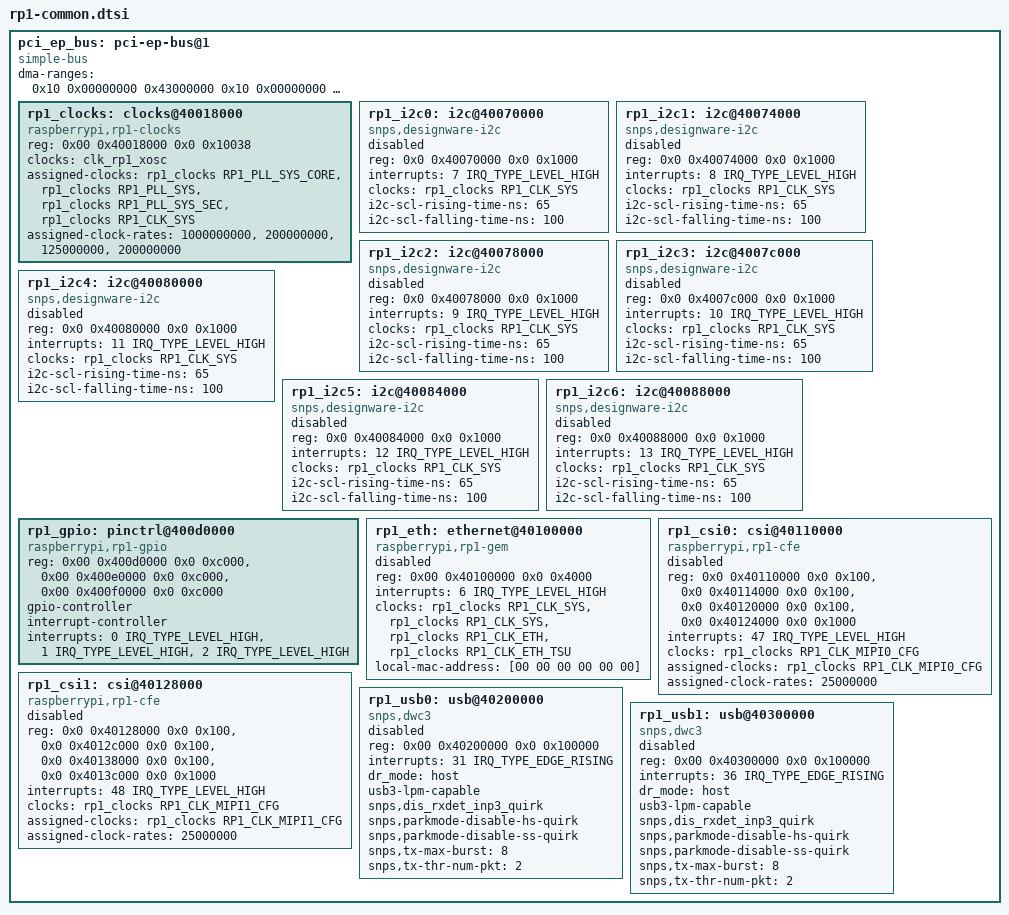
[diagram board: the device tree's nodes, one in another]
// SPDX-License-Identifier: (GPL-2.0 OR MIT)

#include <dt-bindings/gpio/gpio.h>
#include <dt-bindings/interrupt-controller/irq.h>
#include <dt-bindings/clock/raspberrypi,rp1-clocks.h>

pci_ep_bus: pci-ep-bus@1 {
	compatible = "simple-bus";
	ranges = <0x00 0x40000000  0x01 0x00 0x00000000  0x00 0x00400000>;
	dma-ranges = <0x10 0x00000000  0x43000000 0x10 0x00000000  0x10 0x00000000>;
	#address-cells = <2>;
	#size-cells = <2>;

	rp1_clocks: clocks@40018000 {
		compatible = "raspberrypi,rp1-clocks";
		reg = <0x00 0x40018000 0x0 0x10038>;
		#clock-cells = <1>;
		clocks = <&clk_rp1_xosc>;
		assigned-clocks = <&rp1_clocks RP1_PLL_SYS_CORE>,
				  <&rp1_clocks RP1_PLL_SYS>,
				  <&rp1_clocks RP1_PLL_SYS_SEC>,
				  <&rp1_clocks RP1_CLK_SYS>;
		assigned-clock-rates = <1000000000>, // RP1_PLL_SYS_CORE
				       <200000000>,  // RP1_PLL_SYS
				       <125000000>,  // RP1_PLL_SYS_SEC
				       <200000000>;  // RP1_CLK_SYS
	};

	rp1_i2c0: i2c@40070000 {
		compatible = "snps,designware-i2c";
		reg = <0x0 0x40070000  0x0 0x1000>;
		interrupts = <7 IRQ_TYPE_LEVEL_HIGH>;
		clocks = <&rp1_clocks RP1_CLK_SYS>;
		i2c-scl-rising-time-ns = <65>;
		i2c-scl-falling-time-ns = <100>;

		status = "disabled";
	};

	rp1_i2c1: i2c@40074000 {
		compatible = "snps,designware-i2c";
		reg = <0x0 0x40074000  0x0 0x1000>;
		interrupts = <8 IRQ_TYPE_LEVEL_HIGH>;
		clocks = <&rp1_clocks RP1_CLK_SYS>;
		i2c-scl-rising-time-ns = <65>;
		i2c-scl-falling-time-ns = <100>;

		status = "disabled";
	};

	rp1_i2c2: i2c@40078000 {
		compatible = "snps,designware-i2c";
		reg = <0x0 0x40078000  0x0 0x1000>;
		interrupts = <9 IRQ_TYPE_LEVEL_HIGH>;
		clocks = <&rp1_clocks RP1_CLK_SYS>;
		i2c-scl-rising-time-ns = <65>;
		i2c-scl-falling-time-ns = <100>;

		status = "disabled";
	};

	rp1_i2c3: i2c@4007c000 {
		compatible = "snps,designware-i2c";
		reg = <0x0 0x4007c000  0x0 0x1000>;
		interrupts = <10 IRQ_TYPE_LEVEL_HIGH>;
		clocks = <&rp1_clocks RP1_CLK_SYS>;
		i2c-scl-rising-time-ns = <65>;
		i2c-scl-falling-time-ns = <100>;

		status = "disabled";
	};

	rp1_i2c4: i2c@40080000 {
		compatible = "snps,designware-i2c";
		reg = <0x0 0x40080000  0x0 0x1000>;
		interrupts = <11 IRQ_TYPE_LEVEL_HIGH>;
		clocks = <&rp1_clocks RP1_CLK_SYS>;
		i2c-scl-rising-time-ns = <65>;
		i2c-scl-falling-time-ns = <100>;

		status = "disabled";
	};

	rp1_i2c5: i2c@40084000 {
		compatible = "snps,designware-i2c";
		reg = <0x0 0x40084000  0x0 0x1000>;
		interrupts = <12 IRQ_TYPE_LEVEL_HIGH>;
		clocks = <&rp1_clocks RP1_CLK_SYS>;
		i2c-scl-rising-time-ns = <65>;
		i2c-scl-falling-time-ns = <100>;

		status = "disabled";
	};

	rp1_i2c6: i2c@40088000 {
		compatible = "snps,designware-i2c";
		reg = <0x0 0x40088000  0x0 0x1000>;
		interrupts = <13 IRQ_TYPE_LEVEL_HIGH>;
		clocks = <&rp1_clocks RP1_CLK_SYS>;
		i2c-scl-rising-time-ns = <65>;
		i2c-scl-falling-time-ns = <100>;

		status = "disabled";
	};

	rp1_gpio: pinctrl@400d0000 {
		compatible = "raspberrypi,rp1-gpio";
		reg = <0x00 0x400d0000  0x0 0xc000>,
		      <0x00 0x400e0000  0x0 0xc000>,
		      <0x00 0x400f0000  0x0 0xc000>;
		gpio-controller;
		#gpio-cells = <2>;
		interrupt-controller;
		#interrupt-cells = <2>;
		interrupts = <0 IRQ_TYPE_LEVEL_HIGH>,
			     <1 IRQ_TYPE_LEVEL_HIGH>,
			     <2 IRQ_TYPE_LEVEL_HIGH>;
	};

	rp1_eth: ethernet@40100000 {
		compatible = "raspberrypi,rp1-gem";
		reg = <0x00 0x40100000  0x0 0x4000>;
		interrupts = <6 IRQ_TYPE_LEVEL_HIGH>;
		clocks = <&rp1_clocks RP1_CLK_SYS>,
			 <&rp1_clocks RP1_CLK_SYS>,
			 <&rp1_clocks RP1_CLK_ETH>,
			 <&rp1_clocks RP1_CLK_ETH_TSU>;
		clock-names = "pclk", "hclk", "tx_clk", "tsu_clk";
		local-mac-address = [00 00 00 00 00 00];
		status = "disabled";

		#address-cells = <1>;
		#size-cells = <0>;
	};

	rp1_csi0: csi@40110000 {
		compatible = "raspberrypi,rp1-cfe";
		reg = <0x0 0x40110000  0x0 0x100>, // CSI2 DMA address
		      <0x0 0x40114000  0x0 0x100>, // PHY/CSI Host address
		      <0x0 0x40120000  0x0 0x100>, // MIPI CFG address
		      <0x0 0x40124000  0x0 0x1000>; // PiSP FE address
		interrupts = <47 IRQ_TYPE_LEVEL_HIGH>;
		clocks = <&rp1_clocks RP1_CLK_MIPI0_CFG>;
		assigned-clocks = <&rp1_clocks RP1_CLK_MIPI0_CFG>;
		assigned-clock-rates = <25000000>;

		status = "disabled";
	};

	rp1_csi1: csi@40128000 {
		compatible = "raspberrypi,rp1-cfe";
		reg = <0x0 0x40128000  0x0 0x100>, // CSI2 DMA address
		      <0x0 0x4012c000  0x0 0x100>, // PHY/CSI Host address
		      <0x0 0x40138000  0x0 0x100>, // MIPI CFG address
		      <0x0 0x4013c000  0x0 0x1000>; // PiSP FE address
		interrupts = <48 IRQ_TYPE_LEVEL_HIGH>;
		clocks = <&rp1_clocks RP1_CLK_MIPI1_CFG>;
		assigned-clocks = <&rp1_clocks RP1_CLK_MIPI1_CFG>;
		assigned-clock-rates = <25000000>;

		status = "disabled";
	};

	rp1_usb0: usb@40200000 {
		compatible = "snps,dwc3";
		reg = <0x00 0x40200000  0x0 0x100000>;
		interrupts = <31 IRQ_TYPE_EDGE_RISING>;
		dr_mode = "host";
		usb3-lpm-capable;
		snps,dis_rxdet_inp3_quirk;
		snps,parkmode-disable-hs-quirk;
		snps,parkmode-disable-ss-quirk;
		snps,tx-max-burst = /bits/ 8 <8>;
		snps,tx-thr-num-pkt = /bits/ 8 <2>;
		status = "disabled";
	};

	rp1_usb1: usb@40300000 {
		compatible = "snps,dwc3";
		reg = <0x00 0x40300000  0x0 0x100000>;
		interrupts = <36 IRQ_TYPE_EDGE_RISING>;
		dr_mode = "host";
		usb3-lpm-capable;
		snps,dis_rxdet_inp3_quirk;
		snps,parkmode-disable-hs-quirk;
		snps,parkmode-disable-ss-quirk;
		snps,tx-max-burst = /bits/ 8 <8>;
		snps,tx-thr-num-pkt = /bits/ 8 <2>;
		status = "disabled";
	};
};
